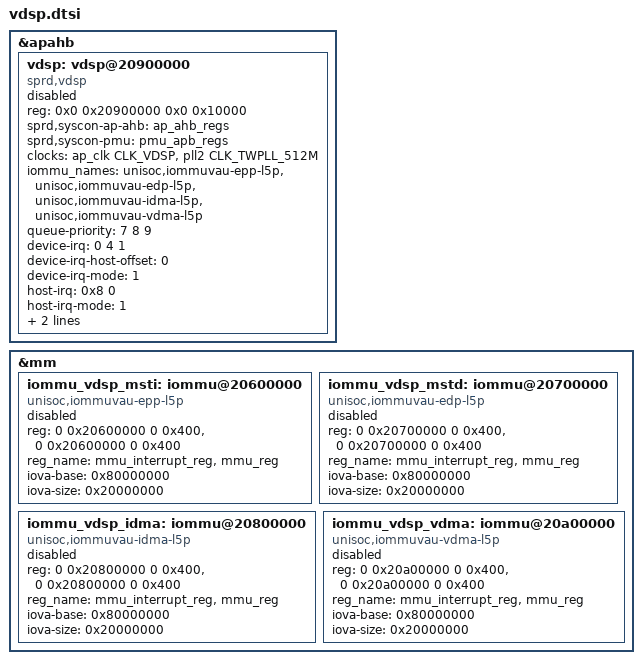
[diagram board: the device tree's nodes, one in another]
// SPDX-License-Identifier: GPL-2.0-only
/*
 * Unisoc VDSP dts file
 *
 * Copyright (C) 2021, Unisoc Inc.
 */

&apahb {
	vdsp: vdsp@20900000 {
		compatible = "sprd,vdsp";
		/* IPI */
		reg = <0x0 0x20900000 0x0 0x10000>;
		sprd,syscon-ap-ahb = <&ap_ahb_regs>;
		sprd,syscon-pmu = <&pmu_apb_regs>;
		clock-names = "vdsp_clk_set","vdsp_clk_512";
		clocks = <&ap_clk CLK_VDSP>,
				 <&pll2  CLK_TWPLL_512M>;
		iommu_names = "unisoc,iommuvau-epp-l5p",
					"unisoc,iommuvau-edp-l5p",
					"unisoc,iommuvau-idma-l5p",
					"unisoc,iommuvau-vdma-l5p";
		queue-priority = <7 8 9>;
		/* offset, bit#, IRQ# */
		device-irq = <0 4 1>;
		device-irq-host-offset = <0>;
		device-irq-mode = <1>;
		/* offset, bit# */
		host-irq = <0x8 0>;
		host-irq-mode = <1>;
		interrupts = <GIC_SPI 169 IRQ_TYPE_LEVEL_HIGH>;
		firmware-name = "vdsp_firmware.bin";
		status = "disabled";
	};
};

&mm {
	iommu_vdsp_msti: iommu@20600000 {
		compatible = "unisoc,iommuvau-epp-l5p";
		reg = <0 0x20600000 0 0x400>,
			  <0 0x20600000 0 0x400>;
		reg_name = "mmu_interrupt_reg","mmu_reg";
		iova-base = <0x80000000>;
		iova-size = <0x20000000>;
		status = "disabled";
		#iommu-cells = <0>;
	};

	iommu_vdsp_mstd: iommu@20700000 {
		compatible = "unisoc,iommuvau-edp-l5p";
		reg = <0 0x20700000 0 0x400>,
			  <0 0x20700000 0 0x400>;
		reg_name = "mmu_interrupt_reg","mmu_reg";
		iova-base = <0x80000000>;
		iova-size = <0x20000000>;
		status = "disabled";
		#iommu-cells = <0>;
	};

	iommu_vdsp_idma: iommu@20800000 {
		compatible = "unisoc,iommuvau-idma-l5p";
		reg = <0 0x20800000 0 0x400>,
			  <0 0x20800000 0 0x400>;
		reg_name = "mmu_interrupt_reg","mmu_reg";
		iova-base = <0x80000000>;
		iova-size = <0x20000000>;
		status = "disabled";
		#iommu-cells = <0>;
	};

	iommu_vdsp_vdma: iommu@20a00000 {
		compatible = "unisoc,iommuvau-vdma-l5p";
		reg = <0 0x20a00000 0 0x400>,
			  <0 0x20a00000 0 0x400>;
		reg_name = "mmu_interrupt_reg","mmu_reg";
		iova-base = <0x80000000>;
		iova-size = <0x20000000>;
		status = "disabled";
		#iommu-cells = <0>;
	};
};
